# ESP32-P4 register map
Vendor: ESPRESSIF SYSTEMS (SHANGHAI) CO., LTD.; Series: ESP32 P-Series; File version: 3
CPU: RV32IMAFC r0p0, little endian, no MPU, FPU, 0 interrupt priority bits
Address unit: 32 bits
Registers are 32-bit, read-write, reset 0x0 unless marked. A register's access mark holds for its fields unless they carry their own. Offsets are from the block's base; [hi:lo] are bit positions.

## MIPI_CSI_BRIDGE — MIPI Camera Interface Bridge
Base 0x5009F800
0x00 CLK_EN — csi bridge register mapping unit clock gating.
  [0] CLK_EN — 0: enable clock gating. 1: disable clock gating, clock always on.
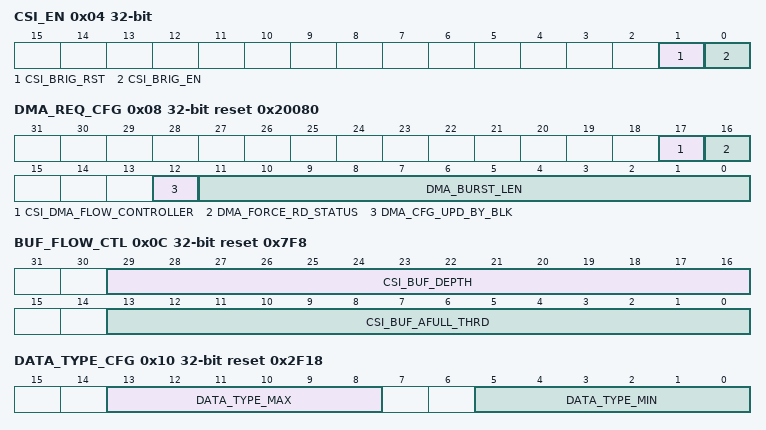
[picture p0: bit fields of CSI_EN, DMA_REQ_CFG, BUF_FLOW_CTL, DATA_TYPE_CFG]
0x04 CSI_EN — csi bridge enable.
  [1] CSI_BRIG_RST — 0: release csi bridge reset. 1: enable csi bridge reset.
  [0] CSI_BRIG_EN — 0: disable csi bridge. 1: enable csi bridge.
0x08 DMA_REQ_CFG reset 0x20080 — dma request configuration.
  [17] CSI_DMA_FLOW_CONTROLLER — 0: dma as flow controller. 1: csi_bridge as flow controller
  [16] DMA_FORCE_RD_STATUS — 1: mask dma request when reading frame info. 0: disable mask.
  [12] DMA_CFG_UPD_BY_BLK — 1: reg_dma_burst_len & reg_dma_burst_len will be updated by dma block finish. 0: updated by frame.
  [11:0] DMA_BURST_LEN — DMA burst length.
0x0C BUF_FLOW_CTL access per field reset 0x7F8 — csi bridge buffer control.
  [29:16] CSI_BUF_DEPTH ro — buffer data count.
  [13:0] CSI_BUF_AFULL_THRD rw — buffer almost full threshold.
0x10 DATA_TYPE_CFG reset 0x2F18 — pixel data type configuration.
  [13:8] DATA_TYPE_MAX — the max value of data type used for pixel filter.
  [5:0] DATA_TYPE_MIN — the min value of data type used for pixel filter.
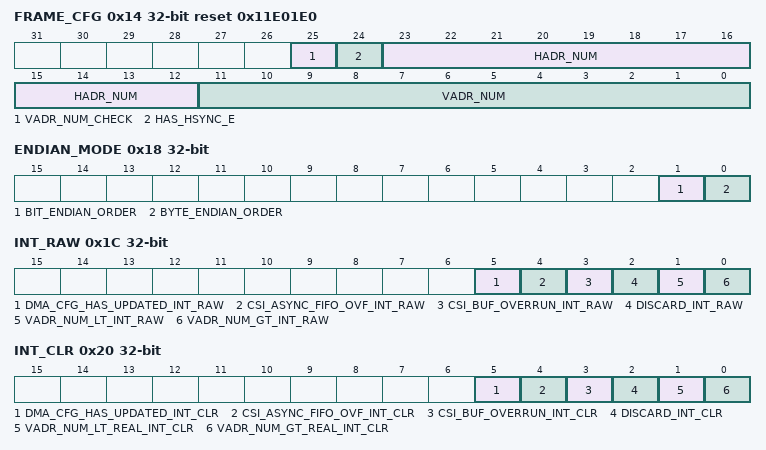
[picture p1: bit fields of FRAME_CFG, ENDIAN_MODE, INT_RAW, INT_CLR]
0x14 FRAME_CFG reset 0x11E01E0 — frame configuration.
  [25] VADR_NUM_CHECK — 0: disable vadr check. 1: enable vadr check.
  [24] HAS_HSYNC_E — 0: frame data doesn't contain hsync. 1: frame data contains hsync.
  [23:12] HADR_NUM — hadr of frame data.
  [11:0] VADR_NUM — vadr of frame data.
0x18 ENDIAN_MODE — data endianness order configuration.
  [1] BIT_ENDIAN_ORDER
  [0] BYTE_ENDIAN_ORDER — endianness order in bytes. 2'h0 is normal mode and 2'h3 is useful to YUV420(Legacy) when isp is bapassed.
0x1C INT_RAW — csi bridge interrupt raw.
  [5] DMA_CFG_HAS_UPDATED_INT_RAW — dma configuration update complete interrupt raw.
  [4] CSI_ASYNC_FIFO_OVF_INT_RAW — buffer overflow interrupt raw.
  [3] CSI_BUF_OVERRUN_INT_RAW — buffer overrun interrupt raw.
  [2] DISCARD_INT_RAW — an incomplete frame of data was sent interrupt raw.
  [1] VADR_NUM_LT_INT_RAW — reg_vadr_num is less than real interrupt raw.
  [0] VADR_NUM_GT_INT_RAW — reg_vadr_num is greater than real interrupt raw.
0x20 INT_CLR wo — csi bridge interrupt clr.
  [5] DMA_CFG_HAS_UPDATED_INT_CLR — dma configuration update complete interrupt clr.
  [4] CSI_ASYNC_FIFO_OVF_INT_CLR — buffer overflow interrupt clr.
  [3] CSI_BUF_OVERRUN_INT_CLR — buffer overrun interrupt clr.
  [2] DISCARD_INT_CLR — an incomplete frame of data was sent interrupt clr.
  [1] VADR_NUM_LT_REAL_INT_CLR — reg_vadr_num is less than real interrupt clr.
  [0] VADR_NUM_GT_REAL_INT_CLR — reg_vadr_num is greater than real interrupt clr.
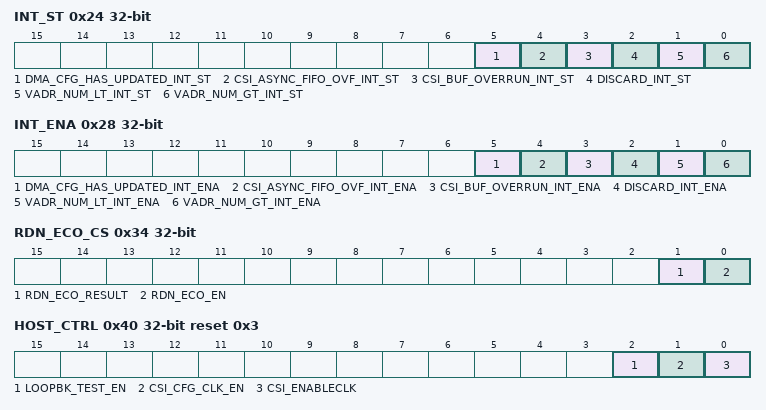
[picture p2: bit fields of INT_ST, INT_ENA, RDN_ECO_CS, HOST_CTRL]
0x24 INT_ST ro — csi bridge interrupt st.
  [5] DMA_CFG_HAS_UPDATED_INT_ST — dma configuration update complete interrupt st.
  [4] CSI_ASYNC_FIFO_OVF_INT_ST — buffer overflow interrupt st.
  [3] CSI_BUF_OVERRUN_INT_ST — buffer overrun interrupt st.
  [2] DISCARD_INT_ST — an incomplete frame of data was sent interrupt st.
  [1] VADR_NUM_LT_INT_ST — reg_vadr_num is less than real interrupt st.
  [0] VADR_NUM_GT_INT_ST — reg_vadr_num is greater than real interrupt st.
0x28 INT_ENA — csi bridge interrupt enable.
  [5] DMA_CFG_HAS_UPDATED_INT_ENA — dma configuration update complete interrupt enable.
  [4] CSI_ASYNC_FIFO_OVF_INT_ENA — buffer overflow interrupt enable.
  [3] CSI_BUF_OVERRUN_INT_ENA — buffer overrun interrupt enable.
  [2] DISCARD_INT_ENA — an incomplete frame of data was sent interrupt enable.
  [1] VADR_NUM_LT_INT_ENA — reg_vadr_num is less than real interrupt enable.
  [0] VADR_NUM_GT_INT_ENA — reg_vadr_num is greater than real interrupt enable.
0x2C DMA_REQ_INTERVAL reset 0x1 — DMA interval configuration.
  [15:0] DMA_REQ_INTERVAL — 16'b1: 1 cycle. 16'b11: 2 cycle. ... ... 16'hFFFF: 16 cycle.
0x30 DMABLK_SIZE reset 0x1FFF — DMA block size configuration.
  [12:0] DMABLK_SIZE — the number of reg_dma_burst_len in a block
0x34 RDN_ECO_CS access per field
  [1] RDN_ECO_RESULT ro, [0] RDN_ECO_EN rw
0x38 RDN_ECO_LOW
0x3C RDN_ECO_HIGH reset 0xFFFFFFFF
0x40 HOST_CTRL reset 0x3 — csi host control by csi bridge.
  [2] LOOPBK_TEST_EN — for phy test by loopback dsi phy to csi phy.
  [1] CSI_CFG_CLK_EN — enable cfg_clk of csi host module.
  [0] CSI_ENABLECLK — enable clock lane module of csi phy.
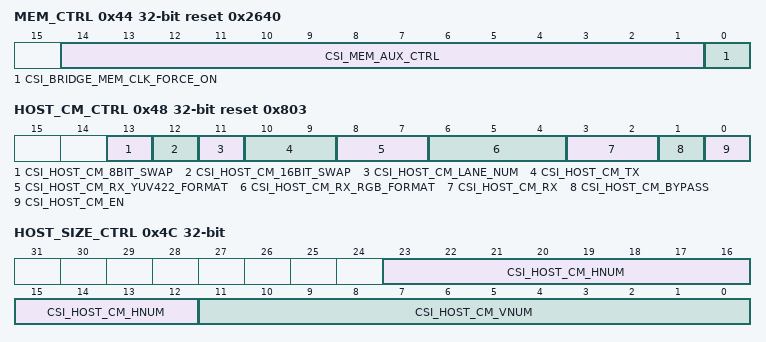
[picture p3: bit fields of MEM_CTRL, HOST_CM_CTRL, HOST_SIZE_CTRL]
0x44 MEM_CTRL reset 0x2640 — csi bridge buffer control.
  [14:1] CSI_MEM_AUX_CTRL
  [0] CSI_BRIDGE_MEM_CLK_FORCE_ON — csi bridge memory clock gating force on.
0x48 HOST_CM_CTRL reset 0x803 — CSI HOST color mode convert configuration.
  [13] CSI_HOST_CM_8BIT_SWAP — Configures whether to swap idi32 high and low 8-bit
  [12] CSI_HOST_CM_16BIT_SWAP — Configures whether to swap idi32 high and low 16-bit
  [11] CSI_HOST_CM_LANE_NUM — Configures lane number that csi used, valid only rgb888 to rgb888. 0: 1-lane, 1: 2-lane
  [10:9] CSI_HOST_CM_TX — Configures whether to bypass cm
  [8:7] CSI_HOST_CM_RX_YUV422_FORMAT — Configures whether to bypass cm
  [6:4] CSI_HOST_CM_RX_RGB_FORMAT — Configures whether to bypass cm
  [3:2] CSI_HOST_CM_RX — Configures whether to bypass cm
  [1] CSI_HOST_CM_BYPASS — Configures whether to bypass cm
  [0] CSI_HOST_CM_EN — Configures whether to enable cm output
0x4C HOST_SIZE_CTRL — CSI HOST color mode convert configuration.
  [23:12] CSI_HOST_CM_HNUM — Configures idi32 image size in x-direction, line_pix_num*bits_per_pix/32 - 1, valid only when yuv422_to_yuv420_en = 1
  [11:0] CSI_HOST_CM_VNUM — Configures idi32 image size in y-direction, row_num - 1, valid only when yuv422_to_yuv420_en = 1
